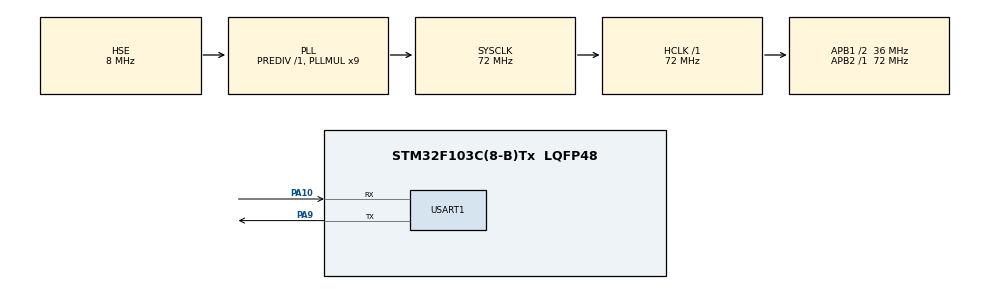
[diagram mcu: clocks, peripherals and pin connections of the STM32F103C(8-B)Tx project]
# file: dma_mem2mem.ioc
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Dma.MEMTOMEM.0.Direction=DMA_MEMORY_TO_MEMORY
Dma.MEMTOMEM.0.Instance=DMA1_Channel1
Dma.MEMTOMEM.0.MemDataAlignment=DMA_MDATAALIGN_BYTE
Dma.MEMTOMEM.0.MemInc=DMA_MINC_ENABLE
Dma.MEMTOMEM.0.Mode=DMA_NORMAL
Dma.MEMTOMEM.0.PeriphDataAlignment=DMA_PDATAALIGN_BYTE
Dma.MEMTOMEM.0.PeriphInc=DMA_PINC_ENABLE
Dma.MEMTOMEM.0.Priority=DMA_PRIORITY_LOW
Dma.Request0=MEMTOMEM
Mcu.Family=STM32F1
Mcu.Name=STM32F103C(8-B)Tx
Mcu.Package=LQFP48
NVIC.DMA1_Channel1_IRQn=true\:0\:0\:false\:false\:true\:true
NVIC.PriorityGroup=NVIC_PRIORITYGROUP_4
PA10.Mode=Asynchronous
PA10.Signal=USART1_RX
PA13.Mode=Serial_Wire
PA13.Signal=SYS_JTMS-SWDIO
PA14.Mode=Serial_Wire
PA14.Signal=SYS_JTCK-SWCLK
PA9.Mode=Asynchronous
PA9.Signal=USART1_TX
PD0-OSC_IN.Mode=HSE-External-Oscillator
PD0-OSC_IN.Signal=RCC_OSC_IN
PD1-OSC_OUT.Mode=HSE-External-Oscillator
PD1-OSC_OUT.Signal=RCC_OSC_OUT
ProjectManager.HeapSize=0x200
ProjectManager.StackSize=0x400
ProjectManager.TargetToolchain=TrueSTUDIO
RCC.AHBFreq_Value=72000000
RCC.APB1CLKDivider=RCC_HCLK_DIV2
RCC.APB1Freq_Value=36000000
RCC.APB1TimFreq_Value=72000000
RCC.APB2Freq_Value=72000000
RCC.APB2TimFreq_Value=72000000
RCC.HCLKFreq_Value=72000000
RCC.PLLMUL=RCC_PLL_MUL9
RCC.PLLSourceVirtual=RCC_PLLSOURCE_HSE
RCC.SYSCLKFreq_VALUE=72000000
RCC.SYSCLKSource=RCC_SYSCLKSOURCE_PLLCLK
RCC.USBFreq_Value=72000000
USART1.VirtualMode=VM_ASYNC
board=custom

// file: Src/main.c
/* USER CODE BEGIN Header */
/**
  ******************************************************************************
  * @file           : main.c
  * @brief          : Main program body
  ******************************************************************************
  ** This notice applies to any and all portions of this file
  * that are not between comment pairs USER CODE BEGIN and
  * USER CODE END. Other portions of this file, whether
  * inserted by the user or by software development tools
  * are owned by their respective copyright owners.
  *
  * COPYRIGHT(c) 2018 STMicroelectronics
  *
  * Redistribution and use in source and binary forms, with or without modification,
  * are permitted provided that the following conditions are met:
  *   1. Redistributions of source code must retain the above copyright notice,
  *      this list of conditions and the following disclaimer.
  *   2. Redistributions in binary form must reproduce the above copyright notice,
  *      this list of conditions and the following disclaimer in the documentation
  *      and/or other materials provided with the distribution.
  *   3. Neither the name of STMicroelectronics nor the names of its contributors
  *      may be used to endorse or promote products derived from this software
  *      without specific prior written permission.
  *
  * THIS SOFTWARE IS PROVIDED BY THE COPYRIGHT HOLDERS AND CONTRIBUTORS "AS IS"
  * AND ANY EXPRESS OR IMPLIED WARRANTIES, INCLUDING, BUT NOT LIMITED TO, THE
  * IMPLIED WARRANTIES OF MERCHANTABILITY AND FITNESS FOR A PARTICULAR PURPOSE ARE
  * DISCLAIMED. IN NO EVENT SHALL THE COPYRIGHT HOLDER OR CONTRIBUTORS BE LIABLE
  * FOR ANY DIRECT, INDIRECT, INCIDENTAL, SPECIAL, EXEMPLARY, OR CONSEQUENTIAL
  * DAMAGES (INCLUDING, BUT NOT LIMITED TO, PROCUREMENT OF SUBSTITUTE GOODS OR
  * SERVICES; LOSS OF USE, DATA, OR PROFITS; OR BUSINESS INTERRUPTION) HOWEVER
  * CAUSED AND ON ANY THEORY OF LIABILITY, WHETHER IN CONTRACT, STRICT LIABILITY,
  * OR TORT (INCLUDING NEGLIGENCE OR OTHERWISE) ARISING IN ANY WAY OUT OF THE USE
  * OF THIS SOFTWARE, EVEN IF ADVISED OF THE POSSIBILITY OF SUCH DAMAGE.
  *
  ******************************************************************************
  */
/* USER CODE END Header */

#include "main.h"

/* USER CODE BEGIN Includes */
#include "string.h"
/* USER CODE END Includes */

/* USER CODE BEGIN PD */
#define BUFFSIZE 20

#define    DWT_CYCCNT    *(volatile unsigned long *)0xE0001004
#define    DWT_CONTROL   *(volatile unsigned long *)0xE0001000
#define    SCB_DEMCR     *(volatile unsigned long *)0xE000EDFC

/* USER CODE END PD */

UART_HandleTypeDef huart1;

DMA_HandleTypeDef hdma_memtomem_dma1_channel1;
/* USER CODE BEGIN PV */

uint8_t src_buff[BUFFSIZE] = {0,};
uint8_t dst_buff[BUFFSIZE] = {0,};
char trans_str[32] = {0,};
uint32_t count_tic = 0;

/* USER CODE END PV */

void SystemClock_Config(void);
static void MX_GPIO_Init(void);
static void MX_DMA_Init(void);
static void MX_USART1_UART_Init(void);

/* USER CODE BEGIN 0 */

void dma1_ch1_m2m_callback(DMA_HandleTypeDef *hdma_memtomem_dma1_channel1) // колбек по окончанию копирования через DMA
{
	count_tic = DWT_CYCCNT;
	snprintf(trans_str, 63, "copydma %lu takt\n", count_tic);
	HAL_UART_Transmit(&huart1, (uint8_t*)trans_str, strlen(trans_str), 1000);
	HAL_UART_Transmit(&huart1, (uint8_t*)"dst_buff=", 9, 1000);
	HAL_UART_Transmit(&huart1, dst_buff, (uint16_t)strlen((const char *)dst_buff), 1000);
	HAL_UART_Transmit(&huart1, (uint8_t*)"---------\n", 10, 1000);
}

void copy_mem_to_mem8(uint8_t *src_buff, uint8_t *dst_buff, int len)
{
  for(int i = 0; i < len; i++)
  {
	  src_buff[i] = dst_buff[i];
  }
}

void copy_mem_to_mem32(uint32_t *src_buff, uint32_t *dst_buff, int len)
{
  for(int i = 0; i < len; i++)
  {
	  src_buff[i] = dst_buff[i];
  }
}

/* USER CODE END 0 */

int main(void)
{

  /* MCU Configuration--------------------------------------------------------*/

  /* Reset of all peripherals, Initializes the Flash interface and the Systick. */
  HAL_Init();

  /* Configure the system clock */
  SystemClock_Config();

  /* Initialize all configured peripherals */
  MX_GPIO_Init();
  MX_DMA_Init();
  MX_USART1_UART_Init();
  /* USER CODE BEGIN 2 */

  // регистрация колбека по окончанию копирования через DMA
  if(HAL_DMA_RegisterCallback(&hdma_memtomem_dma1_channel1, HAL_DMA_XFER_CPLT_CB_ID, dma1_ch1_m2m_callback) != HAL_OK)
  {
      Error_Handler();
  }

  memcpy(src_buff, "istarik.ru stm32\n", BUFFSIZE);
  HAL_UART_Transmit(&huart1, (uint8_t*)"src_buff=", 9, 1000);
  HAL_UART_Transmit(&huart1, src_buff, (uint16_t)strlen((const char *)src_buff), 1000);
  HAL_UART_Transmit(&huart1, (uint8_t*)"\n", 1, 1000);

    ///////////////////////////////////////////////////////////////////////////////////////////
    // измерение скорости копирования (memcpy, вручную, через DMA)
    count_tic = 0;
    SCB_DEMCR |= CoreDebug_DEMCR_TRCENA_Msk;// разрешаем использовать DWT
    DWT_CYCCNT = 0;// обнуляем значение
    DWT_CONTROL|= DWT_CTRL_CYCCNTENA_Msk; // включаем счётчик

    memcpy(dst_buff, src_buff, BUFFSIZE);
    count_tic = DWT_CYCCNT; // кол-во тактов
    snprintf(trans_str, 63, "memcpy8 %lu takt\n", count_tic);
    HAL_UART_Transmit(&huart1, (uint8_t*)trans_str, strlen(trans_str), 1000);

    HAL_UART_Transmit(&huart1, (uint8_t*)"dst_buff=", 9, 1000);
    HAL_UART_Transmit(&huart1, dst_buff, (uint16_t)strlen((const char *)dst_buff), 1000);
    HAL_UART_Transmit(&huart1, (uint8_t*)"\n", 1, 1000);
    memset(dst_buff, 0, BUFFSIZE);

    count_tic = 0;
    DWT_CYCCNT = 0;
    copy_mem_to_mem8(dst_buff, src_buff, BUFFSIZE);
    count_tic = DWT_CYCCNT; // кол-во тактов
    snprintf(trans_str, 63, "copy_mem8 %lu takt\n", count_tic);
    HAL_UART_Transmit(&huart1, (uint8_t*)trans_str, strlen(trans_str), 1000);

    HAL_UART_Transmit(&huart1, (uint8_t*)"dst_buff=", 9, 1000);
    HAL_UART_Transmit(&huart1, dst_buff, (uint16_t)strlen((const char *)dst_buff), 1000);
    HAL_UART_Transmit(&huart1, (uint8_t*)"\n", 1, 1000);
    memset(dst_buff, 0, BUFFSIZE);

    count_tic = 0;
    DWT_CYCCNT = 0;
    copy_mem_to_mem32((uint32_t*)dst_buff, (uint32_t*)src_buff, BUFFSIZE / 4);
    count_tic = DWT_CYCCNT; // кол-во тактов
    snprintf(trans_str, 63, "copy_mem32 %lu takt\n", count_tic);
    HAL_UART_Transmit(&huart1, (uint8_t*)trans_str, strlen(trans_str), 1000);

    HAL_UART_Transmit(&huart1, (uint8_t*)"dst_buff=", 9, 1000);
    HAL_UART_Transmit(&huart1, dst_buff, (uint16_t)strlen((const char *)dst_buff), 1000);
    HAL_UART_Transmit(&huart1, (uint8_t*)"\n", 1, 1000);
    memset(dst_buff, 0, BUFFSIZE);

    count_tic = 0;
    DWT_CYCCNT = 0;
    ///////////////////////////////////////////////////////////////////////////////////////////

  // копирование через DMA
  HAL_DMA_Start_IT(&hdma_memtomem_dma1_channel1, (uint32_t)src_buff, (uint32_t)dst_buff, BUFFSIZE);

  /* USER CODE END 2 */

  /* Infinite loop */
  while (1)
  {

  }
}

void SystemClock_Config(void)
{
  RCC_OscInitTypeDef RCC_OscInitStruct = {0};
  RCC_ClkInitTypeDef RCC_ClkInitStruct = {0};

  /**Initializes the CPU, AHB and APB busses clocks
  */
  RCC_OscInitStruct.OscillatorType = RCC_OSCILLATORTYPE_HSE;
  RCC_OscInitStruct.HSEState = RCC_HSE_ON;
  RCC_OscInitStruct.HSEPredivValue = RCC_HSE_PREDIV_DIV1;
  RCC_OscInitStruct.HSIState = RCC_HSI_ON;
  RCC_OscInitStruct.PLL.PLLState = RCC_PLL_ON;
  RCC_OscInitStruct.PLL.PLLSource = RCC_PLLSOURCE_HSE;
  RCC_OscInitStruct.PLL.PLLMUL = RCC_PLL_MUL9;
  if (HAL_RCC_OscConfig(&RCC_OscInitStruct) != HAL_OK)
  {
    Error_Handler();
  }
  /**Initializes the CPU, AHB and APB busses clocks
  */
  RCC_ClkInitStruct.ClockType = RCC_CLOCKTYPE_HCLK|RCC_CLOCKTYPE_SYSCLK
                              |RCC_CLOCKTYPE_PCLK1|RCC_CLOCKTYPE_PCLK2;
  RCC_ClkInitStruct.SYSCLKSource = RCC_SYSCLKSOURCE_PLLCLK;
  RCC_ClkInitStruct.AHBCLKDivider = RCC_SYSCLK_DIV1;
  RCC_ClkInitStruct.APB1CLKDivider = RCC_HCLK_DIV2;
  RCC_ClkInitStruct.APB2CLKDivider = RCC_HCLK_DIV1;

  if (HAL_RCC_ClockConfig(&RCC_ClkInitStruct, FLASH_LATENCY_2) != HAL_OK)
  {
    Error_Handler();
  }
}

static void MX_USART1_UART_Init(void)
{

  huart1.Instance = USART1;
  huart1.Init.BaudRate = 115200;
  huart1.Init.WordLength = UART_WORDLENGTH_8B;
  huart1.Init.StopBits = UART_STOPBITS_1;
  huart1.Init.Parity = UART_PARITY_NONE;
  huart1.Init.Mode = UART_MODE_TX_RX;
  huart1.Init.HwFlowCtl = UART_HWCONTROL_NONE;
  huart1.Init.OverSampling = UART_OVERSAMPLING_16;
  if (HAL_UART_Init(&huart1) != HAL_OK)
  {
    Error_Handler();
  }

}

static void MX_DMA_Init(void)
{
  /* DMA controller clock enable */
  __HAL_RCC_DMA1_CLK_ENABLE();

  /* Configure DMA request hdma_memtomem_dma1_channel1 on DMA1_Channel1 */
  hdma_memtomem_dma1_channel1.Instance = DMA1_Channel1;
  hdma_memtomem_dma1_channel1.Init.Direction = DMA_MEMORY_TO_MEMORY;
  hdma_memtomem_dma1_channel1.Init.PeriphInc = DMA_PINC_ENABLE;
  hdma_memtomem_dma1_channel1.Init.MemInc = DMA_MINC_ENABLE;
  hdma_memtomem_dma1_channel1.Init.PeriphDataAlignment = DMA_PDATAALIGN_BYTE;
  hdma_memtomem_dma1_channel1.Init.MemDataAlignment = DMA_MDATAALIGN_BYTE;
  hdma_memtomem_dma1_channel1.Init.Mode = DMA_NORMAL;
  hdma_memtomem_dma1_channel1.Init.Priority = DMA_PRIORITY_LOW;
  if (HAL_DMA_Init(&hdma_memtomem_dma1_channel1) != HAL_OK)
  {
    Error_Handler( );
  }

  /* DMA interrupt init */
  /* DMA1_Channel1_IRQn interrupt configuration */
  HAL_NVIC_SetPriority(DMA1_Channel1_IRQn, 0, 0);
  HAL_NVIC_EnableIRQ(DMA1_Channel1_IRQn);

}

static void MX_GPIO_Init(void)
{

  /* GPIO Ports Clock Enable */
  __HAL_RCC_GPIOD_CLK_ENABLE();
  __HAL_RCC_GPIOA_CLK_ENABLE();

}

void Error_Handler(void)
{
}

/************************ (C) COPYRIGHT STMicroelectronics *****END OF FILE****/
